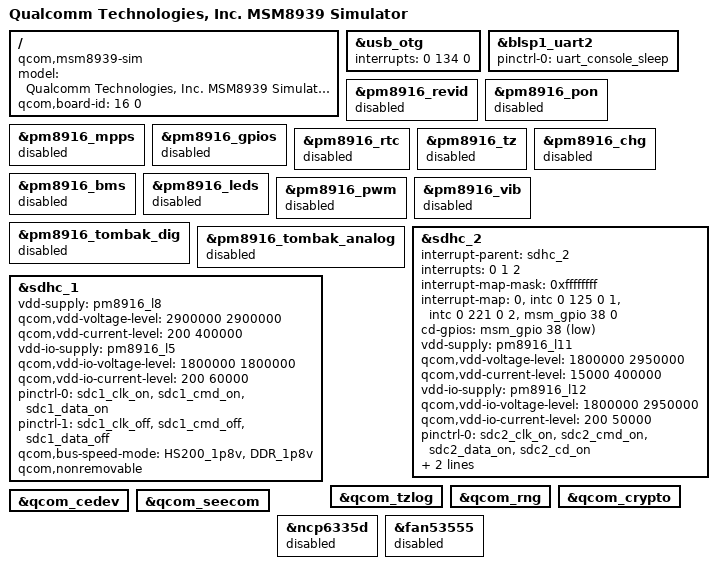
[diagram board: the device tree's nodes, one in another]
/* Copyright (c) 2014, The Linux Foundation. All rights reserved.
 *
 * This program is free software; you can redistribute it and/or modify
 * it under the terms of the GNU General Public License version 2 and
 * only version 2 as published by the Free Software Foundation.
 *
 * This program is distributed in the hope that it will be useful,
 * but WITHOUT ANY WARRANTY; without even the implied warranty of
 * MERCHANTABILITY or FITNESS FOR A PARTICULAR PURPOSE.  See the
 * GNU General Public License for more details.
 */

/dts-v1/;

#include "msm8939.dtsi"
#include "msm8939-pinctrl.dtsi"

/ {
	model = "Qualcomm Technologies, Inc. MSM8939 Simulator";
	compatible = "qcom,msm8939-sim", "qcom,msm8939", "qcom,sim";
	qcom,board-id= <16 0>;
};

&usb_otg {
	interrupts = <0 134 0>;
	interrupt-names = "core_irq";
};

&blsp1_uart2 {
	status = "ok";
	pinctrl-names = "default";
	pinctrl-0 = <&uart_console_sleep>;
};

&pm8916_revid {
	status = "disabled";
};

&pm8916_pon {
	status = "disabled";
};

&pm8916_mpps {
	status = "disabled";
};

&pm8916_gpios {
	status = "disabled";
};

&pm8916_rtc {
	status = "disabled";
};

&pm8916_tz {
	status = "disabled";
};

&pm8916_chg {
	status = "disabled";
};

&pm8916_bms {
	status = "disabled";
};

&pm8916_leds {
	status = "disabled";
};

&pm8916_pwm {
	status = "disabled";
};

&pm8916_vib {
	status = "disabled";
};

&pm8916_tombak_dig {
	status = "disabled";
};

&pm8916_tombak_analog {
	status = "disabled";
};

&sdhc_1 {
	vdd-supply = <&pm8916_l8>;
	qcom,vdd-voltage-level = <2900000 2900000>;
	qcom,vdd-current-level = <200 400000>;

	vdd-io-supply = <&pm8916_l5>;
	qcom,vdd-io-voltage-level = <1800000 1800000>;
	qcom,vdd-io-current-level = <200 60000>;

	pinctrl-names = "active", "sleep";
	pinctrl-0 = <&sdc1_clk_on &sdc1_cmd_on &sdc1_data_on>;
	pinctrl-1 = <&sdc1_clk_off &sdc1_cmd_off &sdc1_data_off>;

	qcom,bus-speed-mode = "HS200_1p8v", "DDR_1p8v";
	qcom,nonremovable;

	status = "ok";
};

&sdhc_2 {
	#address-cells = <0>;
	interrupt-parent = <&sdhc_2>;
	interrupts = <0 1 2>;
	#interrupt-cells = <1>;
	interrupt-map-mask = <0xffffffff>;
	interrupt-map = <0 &intc 0 125 0
			1 &intc 0 221 0
			2 &msm_gpio 38 0>;
	interrupt-names = "hc_irq", "pwr_irq", "status_irq";
	cd-gpios = <&msm_gpio 38 0x1>;

	vdd-supply = <&pm8916_l11>;
	qcom,vdd-voltage-level = <1800000 2950000>;
	qcom,vdd-current-level = <15000 400000>;

	vdd-io-supply = <&pm8916_l12>;
	qcom,vdd-io-voltage-level = <1800000 2950000>;
	qcom,vdd-io-current-level = <200 50000>;

	pinctrl-names = "active", "sleep";
	pinctrl-0 = <&sdc2_clk_on &sdc2_cmd_on &sdc2_data_on &sdc2_cd_on>;
	pinctrl-1 = <&sdc2_clk_off &sdc2_cmd_off &sdc2_data_off &sdc2_cd_off>;

	status = "ok";
};

&qcom_tzlog {
	status = "okay";
};

&qcom_rng {
	status = "okay";
};

&qcom_crypto {
	status = "okay";
};

&qcom_cedev {
	status = "okay";
};

&qcom_seecom {
	status = "okay";
};

&ncp6335d {
	status = "disabled";
};

&fan53555 {
	status = "disabled";
};
